# STM32L422TBY6 register map
File version: 1.0
Registers are 32-bit, access not given, reset 0x0 unless marked. A register's access mark holds for its fields unless they carry their own. Offsets are from the block's base; [hi:lo] are bit positions; {n}, {i} and the like mark numbered series; 'fields as' and 'values as' point back to an identical list.

## COMP1
Base 0x40010200
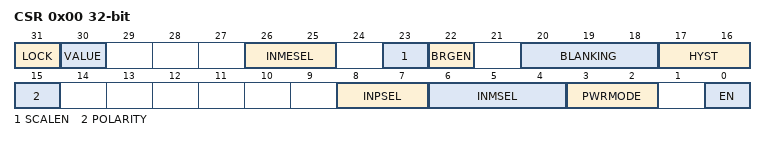
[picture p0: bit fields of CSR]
0x00 CSR
  [31] LOCK, [30] VALUE, [26:25] INMESEL, [23] SCALEN, [22] BRGEN, [20:18] BLANKING, [17:16] HYST, [15] POLARITY, [8:7] INPSEL, [6:4] INMSEL, [3:2] PWRMODE, [0] EN

## EXTI
Base 0x40010400
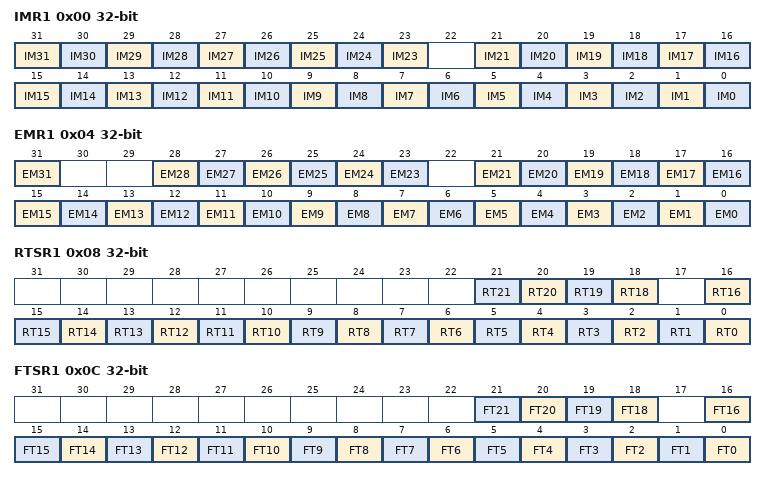
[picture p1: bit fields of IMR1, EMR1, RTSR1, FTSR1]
0x00 IMR1
  [n] IM{n} (n=23..31), [n] IM{n} (n=0..21)
0x04 EMR1
  [31] EM31, [n] EM{n} (n=23..28), [n] EM{n} (n=0..21)
0x08 RTSR1
  [n] RT{n} (n=18..21), [n] RT{n} (n=0..16)
0x0C FTSR1
  [n] FT{n} (n=18..21), [n] FT{n} (n=0..16)
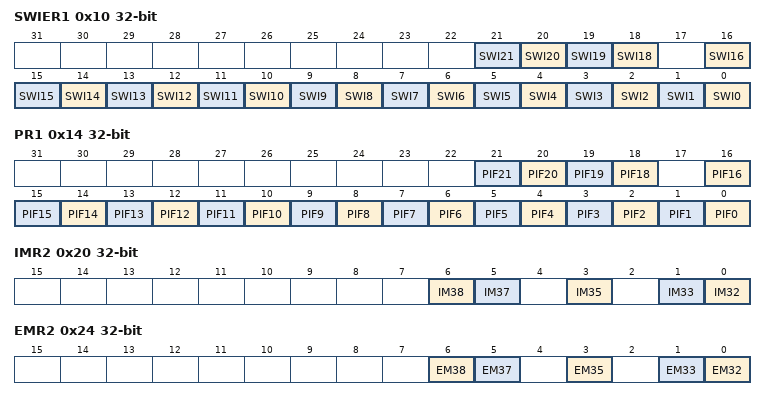
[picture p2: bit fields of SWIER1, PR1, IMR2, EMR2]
0x10 SWIER1
  [n] SWI{n} (n=18..21), [n] SWI{n} (n=0..16)
0x14 PR1
  [n] PIF{n} (n=18..21), [n] PIF{n} (n=0..16)
0x20 IMR2
  [6] IM38, [5] IM37, [3] IM35, [1] IM33, [0] IM32
0x24 EMR2
  [6] EM38, [5] EM37, [3] EM35, [1] EM33, [0] EM32
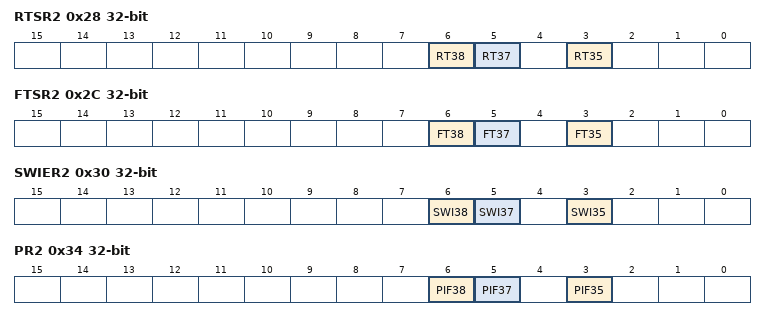
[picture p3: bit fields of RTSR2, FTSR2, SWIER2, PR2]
0x28 RTSR2
  [6] RT38, [5] RT37, [3] RT35
0x2C FTSR2
  [6] FT38, [5] FT37, [3] FT35
0x30 SWIER2
  [6] SWI38, [5] SWI37, [3] SWI35
0x34 PR2
  [6] PIF38, [5] PIF37, [3] PIF35

## FIREWALL
Base 0x40011C00
0x00 CSSA
0x04 CSL
0x08 NVDSSA
0x0C NVDSL
0x10 VDSSA
0x14 VDSL
0x20 CR

## DMA1
Base 0x40020000
Same registers: DMA2 0x40020400
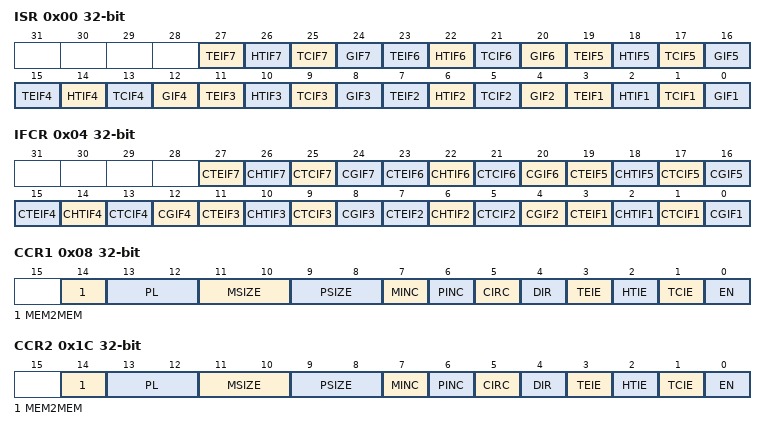
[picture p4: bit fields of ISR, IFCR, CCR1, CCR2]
0x00 ISR
  [4n-1] TEIF{n} (n=1..7), [4n-2] HTIF{n} (n=1..7), [4n-3] TCIF{n} (n=1..7), [4n-4] GIF{n} (n=1..7)
0x04 IFCR
  [4n-1] CTEIF{n} (n=1..7), [4n-2] CHTIF{n} (n=1..7), [4n-3] CTCIF{n} (n=1..7), [4n-4] CGIF{n} (n=1..7)
0x08 CCR1
  [14] MEM2MEM, [13:12] PL, [11:10] MSIZE, [9:8] PSIZE, [7] MINC, [6] PINC, [5] CIRC, [4] DIR, [3] TEIE, [2] HTIE, [1] TCIE, [0] EN
0x0C CNDTR1
  [15:0] NDT
0x10 CPAR1
  [31:0] PA
{0x0+0x14*i} CMAR{i} (i=1..7)
  [31:0] MA
0x1C CCR2
  fields as CCR1
0x20 CNDTR2
  [15:0] NDT
0x24 CPAR2
  [31:0] PA
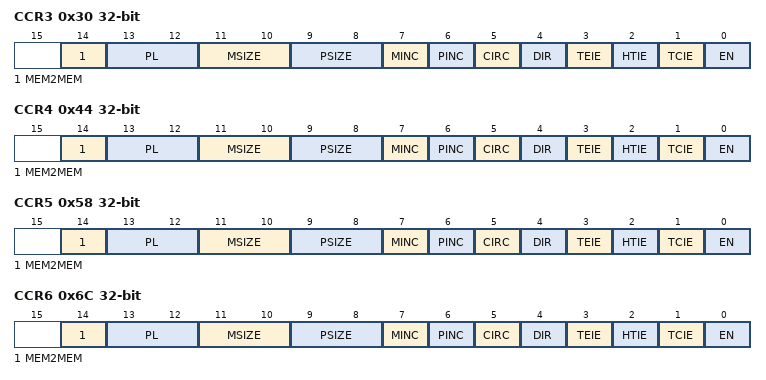
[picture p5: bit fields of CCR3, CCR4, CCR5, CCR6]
0x30 CCR3
  fields as CCR1
0x34 CNDTR3
  [15:0] NDT
0x38 CPAR3
  [31:0] PA
0x44 CCR4
  fields as CCR1
0x48 CNDTR4
  [15:0] NDT
0x4C CPAR4
  [31:0] PA
0x58 CCR5
  fields as CCR1
0x5C CNDTR5
  [15:0] NDT
0x60 CPAR5
  [31:0] PA
0x6C CCR6
  fields as CCR1
0x70 CNDTR6
  [15:0] NDT
0x74 CPAR6
  [31:0] PA
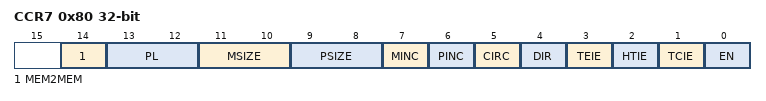
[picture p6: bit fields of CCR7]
0x80 CCR7
  fields as CCR1
0x84 CNDTR7
  [15:0] NDT
0x88 CPAR7
  [31:0] PA

## DMA1_CSELR
Base 0x400200A8
Same registers: DMA2_CSELR 0x400204A8
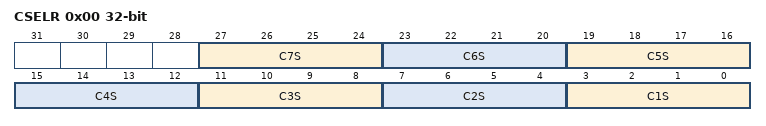
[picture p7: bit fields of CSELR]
0x00 CSELR
  [4n-1:4n-4] C{n}S (n=1..7)

## RCC
Base 0x40021000
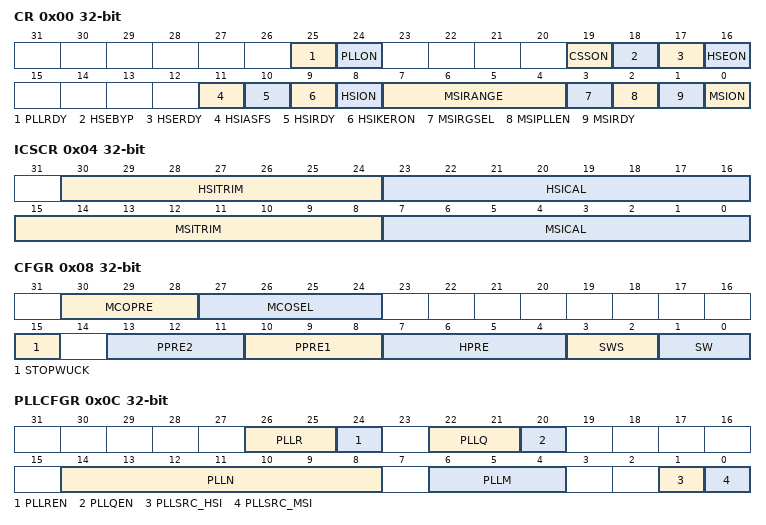
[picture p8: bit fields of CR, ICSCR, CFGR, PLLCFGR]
0x00 CR
  [25] PLLRDY, [24] PLLON, [19] CSSON, [18] HSEBYP, [17] HSERDY, [16] HSEON, [11] HSIASFS, [10] HSIRDY, [9] HSIKERON, [8] HSION, [7:4] MSIRANGE, [3] MSIRGSEL, [2] MSIPLLEN, [1] MSIRDY, [0] MSION
0x04 ICSCR
  [30:24] HSITRIM, [23:16] HSICAL, [15:8] MSITRIM, [7:0] MSICAL
0x08 CFGR
  [30:28] MCOPRE, [27:24] MCOSEL, [15] STOPWUCK, [13:11] PPRE2, [10:8] PPRE1, [7:4] HPRE, [3:2] SWS, [1:0] SW
0x0C PLLCFGR
  [26:25] PLLR, [24] PLLREN, [22:21] PLLQ, [20] PLLQEN, [14:8] PLLN, [6:4] PLLM, [1] PLLSRC_HSI, [0] PLLSRC_MSI
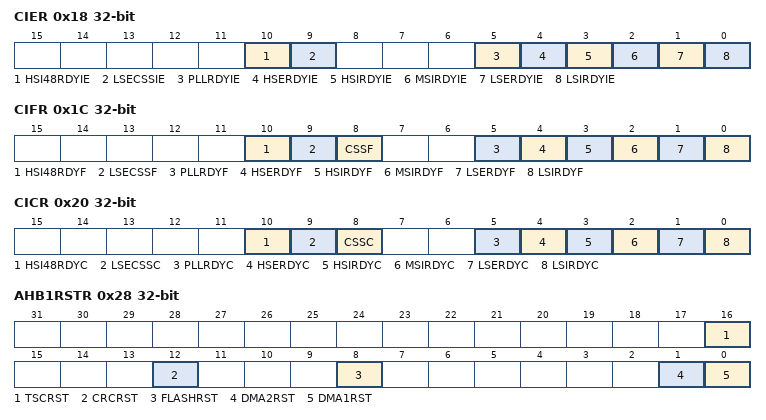
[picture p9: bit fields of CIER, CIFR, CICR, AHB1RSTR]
0x18 CIER
  [10] HSI48RDYIE, [9] LSECSSIE, [5] PLLRDYIE, [4] HSERDYIE, [3] HSIRDYIE, [2] MSIRDYIE, [1] LSERDYIE, [0] LSIRDYIE
0x1C CIFR
  [10] HSI48RDYF, [9] LSECSSF, [8] CSSF, [5] PLLRDYF, [4] HSERDYF, [3] HSIRDYF, [2] MSIRDYF, [1] LSERDYF, [0] LSIRDYF
0x20 CICR
  [10] HSI48RDYC, [9] LSECSSC, [8] CSSC, [5] PLLRDYC, [4] HSERDYC, [3] HSIRDYC, [2] MSIRDYC, [1] LSERDYC, [0] LSIRDYC
0x28 AHB1RSTR
  [16] TSCRST, [12] CRCRST, [8] FLASHRST, [1] DMA2RST, [0] DMA1RST
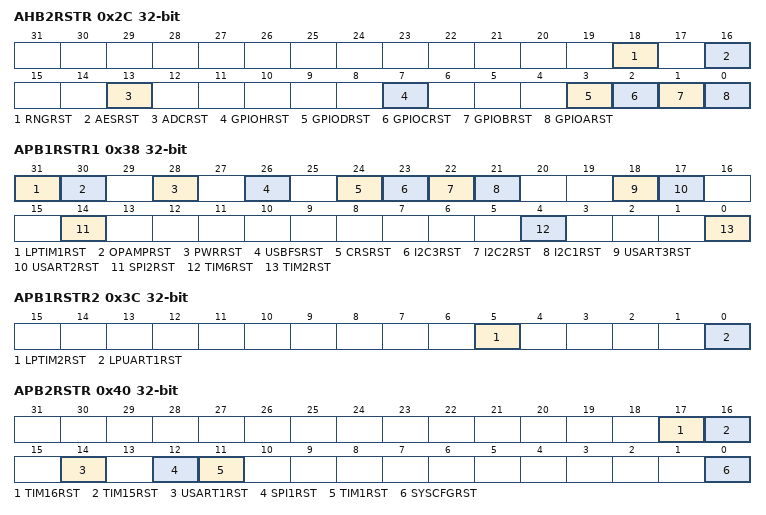
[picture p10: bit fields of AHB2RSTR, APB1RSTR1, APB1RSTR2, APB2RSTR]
0x2C AHB2RSTR
  [18] RNGRST, [16] AESRST, [13] ADCRST, [7] GPIOHRST, [3] GPIODRST, [2] GPIOCRST, [1] GPIOBRST, [0] GPIOARST
0x30 AHB3RSTR
  [8] QSPIRST
0x38 APB1RSTR1
  [31] LPTIM1RST, [30] OPAMPRST, [28] PWRRST, [26] USBFSRST, [24] CRSRST, [23] I2C3RST, [22] I2C2RST, [21] I2C1RST, [18] USART3RST, [17] USART2RST, [14] SPI2RST, [4] TIM6RST, [0] TIM2RST
0x3C APB1RSTR2
  [5] LPTIM2RST, [0] LPUART1RST
0x40 APB2RSTR
  [17] TIM16RST, [16] TIM15RST, [14] USART1RST, [12] SPI1RST, [11] TIM1RST, [0] SYSCFGRST
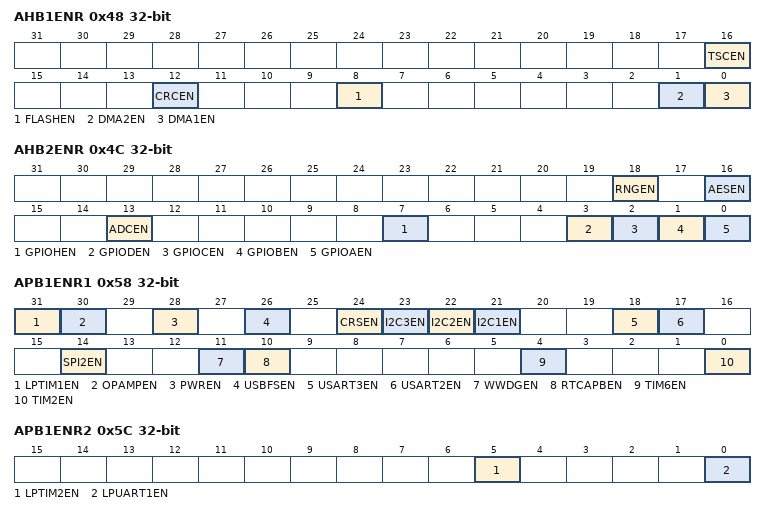
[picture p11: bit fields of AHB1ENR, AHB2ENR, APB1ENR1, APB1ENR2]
0x48 AHB1ENR
  [16] TSCEN, [12] CRCEN, [8] FLASHEN, [1] DMA2EN, [0] DMA1EN
0x4C AHB2ENR
  [18] RNGEN, [16] AESEN, [13] ADCEN, [7] GPIOHEN, [3] GPIODEN, [2] GPIOCEN, [1] GPIOBEN, [0] GPIOAEN
0x50 AHB3ENR
  [8] QSPIEN
0x58 APB1ENR1
  [31] LPTIM1EN, [30] OPAMPEN, [28] PWREN, [26] USBFSEN, [24] CRSEN, [23] I2C3EN, [22] I2C2EN, [21] I2C1EN, [18] USART3EN, [17] USART2EN, [14] SPI2EN, [11] WWDGEN, [10] RTCAPBEN, [4] TIM6EN, [0] TIM2EN
0x5C APB1ENR2
  [5] LPTIM2EN, [0] LPUART1EN
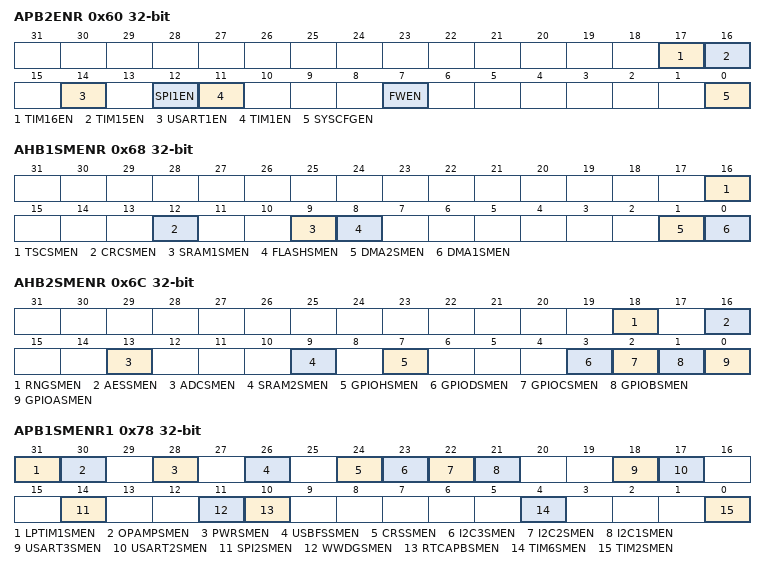
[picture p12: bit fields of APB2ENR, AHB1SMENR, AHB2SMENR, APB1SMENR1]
0x60 APB2ENR
  [17] TIM16EN, [16] TIM15EN, [14] USART1EN, [12] SPI1EN, [11] TIM1EN, [7] FWEN, [0] SYSCFGEN
0x68 AHB1SMENR
  [16] TSCSMEN, [12] CRCSMEN, [9] SRAM1SMEN, [8] FLASHSMEN, [1] DMA2SMEN, [0] DMA1SMEN
0x6C AHB2SMENR
  [18] RNGSMEN, [16] AESSMEN, [13] ADCSMEN, [9] SRAM2SMEN, [7] GPIOHSMEN, [3] GPIODSMEN, [2] GPIOCSMEN, [1] GPIOBSMEN, [0] GPIOASMEN
0x70 AHB3SMENR
  [8] QSPISMEN
0x78 APB1SMENR1
  [31] LPTIM1SMEN, [30] OPAMPSMEN, [28] PWRSMEN, [26] USBFSSMEN, [24] CRSSMEN, [23] I2C3SMEN, [22] I2C2SMEN, [21] I2C1SMEN, [18] USART3SMEN, [17] USART2SMEN, [14] SPI2SMEN, [11] WWDGSMEN, [10] RTCAPBSMEN, [4] TIM6SMEN, [0] TIM2SMEN
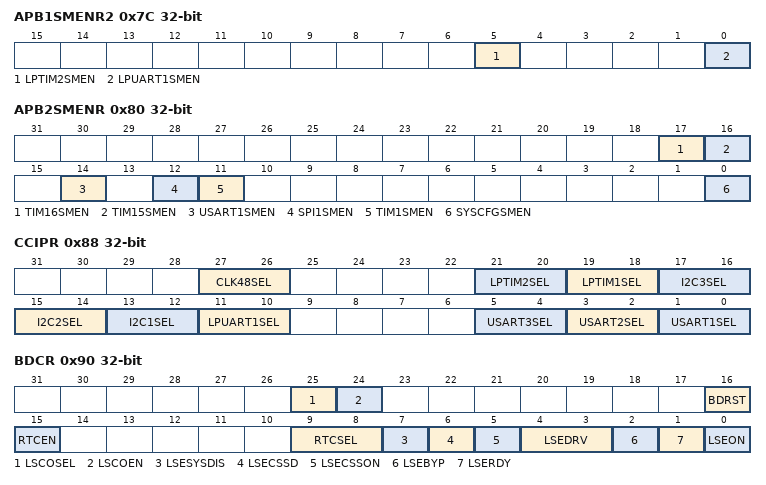
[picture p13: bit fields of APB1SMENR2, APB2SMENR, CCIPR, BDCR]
0x7C APB1SMENR2
  [5] LPTIM2SMEN, [0] LPUART1SMEN
0x80 APB2SMENR
  [17] TIM16SMEN, [16] TIM15SMEN, [14] USART1SMEN, [12] SPI1SMEN, [11] TIM1SMEN, [0] SYSCFGSMEN
0x88 CCIPR
  [27:26] CLK48SEL, [21:20] LPTIM2SEL, [19:18] LPTIM1SEL, [17:16] I2C3SEL, [15:14] I2C2SEL, [13:12] I2C1SEL, [11:10] LPUART1SEL, [5:4] USART3SEL, [3:2] USART2SEL, [1:0] USART1SEL
0x90 BDCR
  [25] LSCOSEL, [24] LSCOEN, [16] BDRST, [15] RTCEN, [9:8] RTCSEL, [7] LSESYSDIS, [6] LSECSSD, [5] LSECSSON, [4:3] LSEDRV, [2] LSEBYP, [1] LSERDY, [0] LSEON
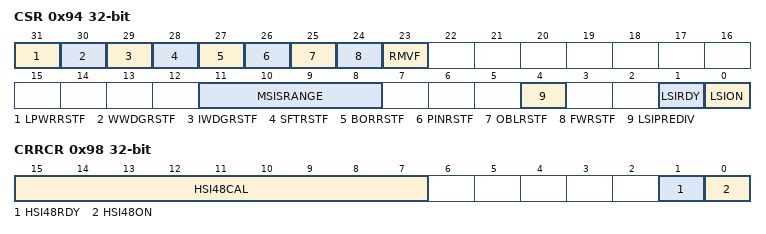
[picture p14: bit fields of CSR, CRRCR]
0x94 CSR
  [31] LPWRRSTF, [30] WWDGRSTF, [29] IWDGRSTF, [28] SFTRSTF, [27] BORRSTF, [26] PINRSTF, [25] OBLRSTF, [24] FWRSTF, [23] RMVF, [11:8] MSISRANGE, [4] LSIPREDIV, [1] LSIRDY, [0] LSION
0x98 CRRCR
  [15:7] HSI48CAL, [1] HSI48RDY, [0] HSI48ON
